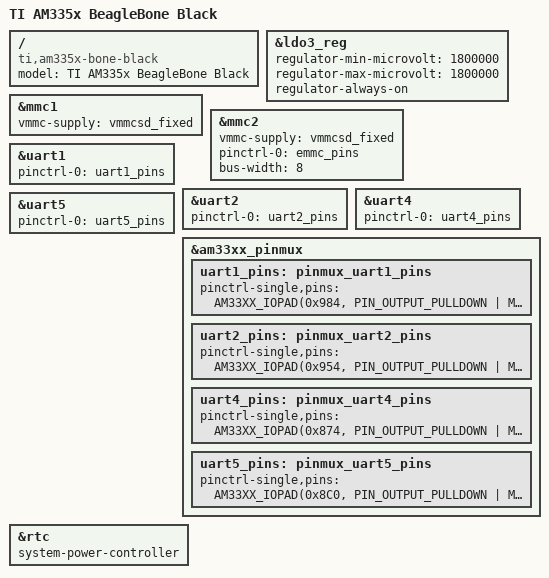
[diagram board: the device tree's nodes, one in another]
/*
 * Copyright (C) 2012 Texas Instruments Incorporated - http://www.ti.com/
 *
 * This program is free software; you can redistribute it and/or modify
 * it under the terms of the GNU General Public License version 2 as
 * published by the Free Software Foundation.
 */
/dts-v1/;

#include "am33xx.dtsi"
#include "am335x-bone-common.dtsi"
#include <dt-bindings/display/tda998x.h>

/ {
	model = "TI AM335x BeagleBone Black";
	compatible = "ti,am335x-bone-black", "ti,am335x-bone", "ti,am33xx";
};

&ldo3_reg {
	regulator-min-microvolt = <1800000>;
	regulator-max-microvolt = <1800000>;
	regulator-always-on;
};

&mmc1 {
	vmmc-supply = <&vmmcsd_fixed>;
};

&mmc2 {
	vmmc-supply = <&vmmcsd_fixed>;
	pinctrl-names = "default";
	pinctrl-0 = <&emmc_pins>;
	bus-width = <8>;
	status = "okay";
};

&uart1 {
	status = "okay";
	pinctrl-names = "default";
	pinctrl-0 = <&uart1_pins>;
};

&uart2 {
	status = "okay";
	pinctrl-names = "default";
	pinctrl-0 = <&uart2_pins>;
};

&uart4 {
	status = "okay";
	pinctrl-names = "default";
	pinctrl-0 = <&uart4_pins>;
};

&uart5 {
	status = "okay";
	pinctrl-names = "default";
	pinctrl-0 = <&uart5_pins>;
};

&am33xx_pinmux {
	uart1_pins: pinmux_uart1_pins {
		pinctrl-single,pins = <
			AM33XX_IOPAD(0x984, PIN_OUTPUT_PULLDOWN | MUX_MODE0)	/* TXD - P9.24 */
			AM33XX_IOPAD(0x980, PIN_INPUT_PULLUP | MUX_MODE0)	/* RXD - P9.26 */
		>;
	};

	uart2_pins: pinmux_uart2_pins {
		pinctrl-single,pins = <
			AM33XX_IOPAD(0x954, PIN_OUTPUT_PULLDOWN | MUX_MODE1)	/* TXD - P9.21 */
			AM33XX_IOPAD(0x950, PIN_INPUT_PULLUP | MUX_MODE1)	/* RXD - P9.22 */
		>;
	};

	uart4_pins: pinmux_uart4_pins {
		pinctrl-single,pins = <
			AM33XX_IOPAD(0x874, PIN_OUTPUT_PULLDOWN | MUX_MODE6)	/* TXD - P9.13 */
			AM33XX_IOPAD(0x870, PIN_INPUT_PULLUP | MUX_MODE6)	/* RXD - P9.11 */
		>;
	};

	uart5_pins: pinmux_uart5_pins {
		pinctrl-single,pins = <
			AM33XX_IOPAD(0x8C0, PIN_OUTPUT_PULLDOWN | MUX_MODE4)	/* TXD - P8.37 */
			AM33XX_IOPAD(0x8C4, PIN_INPUT_PULLUP | MUX_MODE4)	/* RXD - P8.38 */
		>;
	};
};

&rtc {
	system-power-controller;
};

/ {




};
